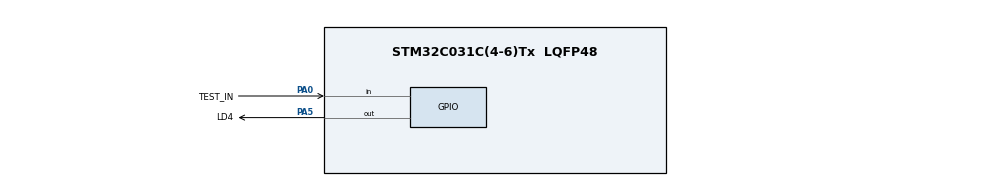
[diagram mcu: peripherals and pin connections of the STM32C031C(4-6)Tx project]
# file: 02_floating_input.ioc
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Mcu.Family=STM32C0
Mcu.Name=STM32C031C(4-6)Tx
Mcu.Package=LQFP48
PA0.GPIO_Label=TEST_IN
PA0.Signal=GPIO_Input
PA13.Mode=Serial_Wire
PA13.Signal=DEBUG_SWDIO
PA14-BOOT0.Mode=Serial_Wire
PA14-BOOT0.Signal=DEBUG_SWCLK
PA5.GPIO_Label=LD4
PA5.Signal=GPIO_Output
ProjectManager.HeapSize=0x200
ProjectManager.StackSize=0x400
ProjectManager.TargetToolchain=STM32CubeIDE
RCC.ADCFreq_Value=12000000
RCC.AHBFreq_Value=12000000
RCC.CortexFreq_Value=12000000
RCC.EXTERNAL_CLOCK_VALUE=12288000
RCC.HCLKFreq_Value=12000000
RCC.HSE_VALUE=8000000
RCC.HSI_VALUE=48000000
RCC.LSE_VALUE=32768
RCC.SYSCLKFreq_VALUE=12000000
board=custom

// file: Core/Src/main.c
/* USER CODE BEGIN Header */
/**
 ******************************************************************************
 * @file           : main.c
 * @brief          : Main program body
 ******************************************************************************
 * @attention
 *
 * Copyright (c) 2026 STMicroelectronics.
 * All rights reserved.
 *
 * This software is licensed under terms that can be found in the LICENSE file
 * in the root directory of this software component.
 * If no LICENSE file comes with this software, it is provided AS-IS.
 *
 ******************************************************************************
 */
/* USER CODE END Header */
#include "main.h"

/* USER CODE BEGIN PD */
#define PULL_MODE 0 // 0: No pull(플로팅), 1: 풀업, 2: 풀다운
/* USER CODE END PD */

void SystemClock_Config(void);
static void MX_GPIO_Init(void);

int main(void) {

	/* MCU Configuration--------------------------------------------------------*/

	/* Reset of all peripherals, Initializes the Flash interface and the Systick.
	 */
	HAL_Init();

	/* Configure the system clock */
	SystemClock_Config();

	/* Initialize all configured peripherals */
	MX_GPIO_Init();
	/* USER CODE BEGIN 2 */
	/* PA0의 풀업/풀다운을 PUPDR 레지스터로 직접 설정 */
	GPIOA->PUPDR = (GPIOA->PUPDR & ~(3U << 0)) | ((uint32_t) PULL_MODE << 0);
	/* USER CODE END 2 */

	/* Infinite loop */
	while (1) {

		/* USER CODE BEGIN 3 */
		if (HAL_GPIO_ReadPin(TEST_IN_GPIO_Port, TEST_IN_Pin) == GPIO_PIN_SET) {
			HAL_GPIO_WritePin(LD4_GPIO_Port, LD4_Pin, GPIO_PIN_SET); // 입력 1 → LED 켜짐
		} else {
			HAL_GPIO_WritePin(LD4_GPIO_Port, LD4_Pin, GPIO_PIN_RESET); // 입력 0 → LED 꺼짐
		}
	}
	/* USER CODE END 3 */
}

void SystemClock_Config(void) {
	RCC_OscInitTypeDef RCC_OscInitStruct = { 0 };
	RCC_ClkInitTypeDef RCC_ClkInitStruct = { 0 };

	__HAL_FLASH_SET_LATENCY(FLASH_LATENCY_0);

	/** Initializes the RCC Oscillators according to the specified parameters
	 * in the RCC_OscInitTypeDef structure.
	 */
	RCC_OscInitStruct.OscillatorType = RCC_OSCILLATORTYPE_HSI;
	RCC_OscInitStruct.HSIState = RCC_HSI_ON;
	RCC_OscInitStruct.HSIDiv = RCC_HSI_DIV4;
	RCC_OscInitStruct.HSICalibrationValue = RCC_HSICALIBRATION_DEFAULT;
	if (HAL_RCC_OscConfig(&RCC_OscInitStruct) != HAL_OK) {
		Error_Handler();
	}

	/** Initializes the CPU, AHB and APB buses clocks
	 */
	RCC_ClkInitStruct.ClockType =
	RCC_CLOCKTYPE_HCLK | RCC_CLOCKTYPE_SYSCLK | RCC_CLOCKTYPE_PCLK1;
	RCC_ClkInitStruct.SYSCLKSource = RCC_SYSCLKSOURCE_HSI;
	RCC_ClkInitStruct.SYSCLKDivider = RCC_SYSCLK_DIV1;
	RCC_ClkInitStruct.AHBCLKDivider = RCC_HCLK_DIV1;
	RCC_ClkInitStruct.APB1CLKDivider = RCC_APB1_DIV1;

	if (HAL_RCC_ClockConfig(&RCC_ClkInitStruct, FLASH_LATENCY_0) != HAL_OK) {
		Error_Handler();
	}
}

static void MX_GPIO_Init(void) {
	GPIO_InitTypeDef GPIO_InitStruct = { 0 };

	/* GPIO Ports Clock Enable */
	__HAL_RCC_GPIOA_CLK_ENABLE();

	/*Configure GPIO pin Output Level */
	HAL_GPIO_WritePin(LD4_GPIO_Port, LD4_Pin, GPIO_PIN_RESET);

	/*Configure GPIO pin : TEST_IN_Pin */
	GPIO_InitStruct.Pin = TEST_IN_Pin;
	GPIO_InitStruct.Mode = GPIO_MODE_INPUT;
	GPIO_InitStruct.Pull = GPIO_NOPULL;
	HAL_GPIO_Init(TEST_IN_GPIO_Port, &GPIO_InitStruct);

	/*Configure GPIO pin : LD4_Pin */
	GPIO_InitStruct.Pin = LD4_Pin;
	GPIO_InitStruct.Mode = GPIO_MODE_OUTPUT_PP;
	GPIO_InitStruct.Pull = GPIO_NOPULL;
	GPIO_InitStruct.Speed = GPIO_SPEED_FREQ_LOW;
	HAL_GPIO_Init(LD4_GPIO_Port, &GPIO_InitStruct);

}

void Error_Handler(void) {
	__disable_irq();
	while (1) {
	}
}
#ifdef USE_FULL_ASSERT
/**
 * @brief  Reports the name of the source file and the source line number
 *         where the assert_param error has occurred.
 * @param  file: pointer to the source file name
 * @param  line: assert_param error line source number
 * @retval None
 */
void assert_failed(uint8_t *file, uint32_t line) {
  /* USER CODE BEGIN 6 */
  /* User can add his own implementation to report the file name and line
     number, ex: printf("Wrong parameters value: file %s on line %d\r\n", file,
     line) */
  /* USER CODE END 6 */
}
#endif /* USE_FULL_ASSERT */
